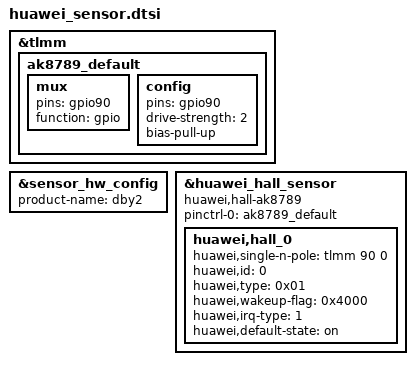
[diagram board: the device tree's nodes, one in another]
&tlmm {
    ak8789_default: ak8789_default {
        mux {
            pins = "gpio90";
            function =  "gpio";
        };
        config {
            pins = "gpio90";
            drive-strength = <2>;
            bias-pull-up;
        };
    };
};

&sensor_hw_config {
    product-name = "dby2";
};

&huawei_hall_sensor {
    compatible = "huawei,hall-ak8789";
    pinctrl-names = "default";
    pinctrl-0 = <&ak8789_default>;
    status = "ok";

    huawei,hall_0 {
        huawei,single-n-pole = <&tlmm 90 0>;
        huawei,id = <0>;
        huawei,type = <0x01>;
        huawei,wakeup-flag = <0x4000>;
        huawei,irq-type = <1>; // trigger mode(0: level 1: edge)
        huawei,default-state = "on";
    };
};
